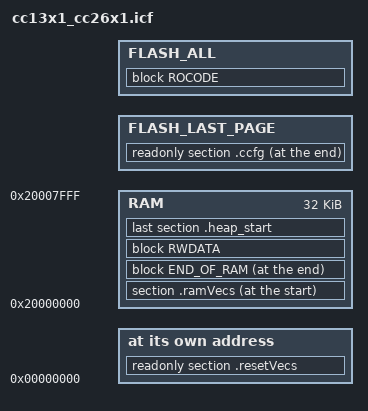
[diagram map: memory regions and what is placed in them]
/******************************************************************************

 @file  cc13x2_cc26x2.icf

 @brief IAR Linker configuration file for cc13x1_cc26x1

 Group: WCS LPC
 Target Device: cc13x2_cc26x2

 ******************************************************************************

 Copyright (c) 2016-2018, Texas Instruments Incorporated
 All rights reserved.

 Redistribution and use in source and binary forms, with or without
 modification, are permitted provided that the following conditions
 are met:

 *  Redistributions of source code must retain the above copyright
    notice, this list of conditions and the following disclaimer.

 *  Redistributions in binary form must reproduce the above copyright
    notice, this list of conditions and the following disclaimer in the
    documentation and/or other materials provided with the distribution.

 *  Neither the name of Texas Instruments Incorporated nor the names of
    its contributors may be used to endorse or promote products derived
    from this software without specific prior written permission.

 THIS SOFTWARE IS PROVIDED BY THE COPYRIGHT HOLDERS AND CONTRIBUTORS "AS IS"
 AND ANY EXPRESS OR IMPLIED WARRANTIES, INCLUDING, BUT NOT LIMITED TO,
 THE IMPLIED WARRANTIES OF MERCHANTABILITY AND FITNESS FOR A PARTICULAR
 PURPOSE ARE DISCLAIMED. IN NO EVENT SHALL THE COPYRIGHT OWNER OR
 CONTRIBUTORS BE LIABLE FOR ANY DIRECT, INDIRECT, INCIDENTAL, SPECIAL,
 EXEMPLARY, OR CONSEQUENTIAL DAMAGES (INCLUDING, BUT NOT LIMITED TO,
 PROCUREMENT OF SUBSTITUTE GOODS OR SERVICES; LOSS OF USE, DATA, OR PROFITS;
 OR BUSINESS INTERRUPTION) HOWEVER CAUSED AND ON ANY THEORY OF LIABILITY,
 WHETHER IN CONTRACT, STRICT LIABILITY, OR TORT (INCLUDING NEGLIGENCE OR
 OTHERWISE) ARISING IN ANY WAY OUT OF THE USE OF THIS SOFTWARE,
 EVEN IF ADVISED OF THE POSSIBILITY OF SUCH DAMAGE.

 *****************************************************************************/

////////////////////////////////////////////////////////////////////////////////
// Memory Sizes
////////////////////////////////////////////////////////////////////////////////
define symbol FLASH_BASE            = 0x00000000;
define symbol RAM_BASE              = 0x20000000;

define symbol RAM_SIZE            = 0x00008000; // 32K
define symbol FLASH_SIZE          = 0x00058000; // 352K

////////////////////////////////////////////////////////////////////////////////
// Memory Definitions
////////////////////////////////////////////////////////////////////////////////

////////////////////////////////////////////////////////////////////////////////
// RAM
//

define symbol RAM_START = RAM_BASE;
define symbol RAM_END = RAM_START+RAM_SIZE-1;

////////////////////////////////////////////////////////////////////////////////
// Flash
//
define symbol WORD_SIZE = 4;

define symbol PAGE_SIZE = 0x2000;
export symbol PAGE_SIZE;

define symbol FLASH_MEM_ALIGN     = WORD_SIZE;

define symbol FLASH_START           = FLASH_BASE;

define symbol NUM_RESERVED_PAGES    = 1;  /*last page i define in FLASH_LAST_PAGE */

define symbol RESERVED_SIZE         = (NUM_RESERVED_PAGES * PAGE_SIZE);

define symbol FLASH_END             = FLASH_SIZE - RESERVED_SIZE - 1;


////////////////////////////////////////////////////////////////////////////////
// Stack
//

define symbol STACK_SIZE          = 0x400;
define symbol STACK_START         = RAM_END + 1;
define symbol STACK_END           = STACK_START - STACK_SIZE;
//
define symbol STACK_TOP           = RAM_END + 1;
export symbol STACK_TOP;

////////////////////////////////////////////////////////////////////////////////
// Flash Interrupt Vector Table
//

define symbol INTVEC_NUM_ENTRIES  = 50 + 1; // first entry is stack location
define symbol INTVEC_SIZE         = INTVEC_NUM_ENTRIES + 4;

////////////////////////////////////////////////////////////////////////////////
// Memory Regions
////////////////////////////////////////////////////////////////////////////////

define memory mem with size = 4G;

define region RAM                 = mem:[from RAM_START   to RAM_END];
define region FLASH_LAST_PAGE     = mem:[from(FLASH_SIZE) - PAGE_SIZE to FLASH_SIZE-1];
define region FLASH               = mem:[from FLASH_START to FLASH_END];
define region FLASH_ALL           = mem:[from FLASH_START to FLASH_END] |
                                         FLASH_LAST_PAGE;

////////////////////////////////////////////////////////////////////////////////
// Memory Placement
////////////////////////////////////////////////////////////////////////////////

// Code and RO Data
define block ROCODE                           { ro };
//place in FLASH { readonly };

// CCFG
place at end of FLASH_LAST_PAGE { readonly section .ccfg };
keep { section .ccfg };

// Interrupt Vector Table
place at address mem:FLASH_START { readonly section .resetVecs };
keep                             { readonly section .resetVecs };

// All other pieces of codes:
place in FLASH_ALL { block ROCODE };

// RAM Vector Table
place at start of RAM { section .ramVecs };

// Runtime Stack
define block CSTACK with alignment = 8, size = STACK_SIZE { section .stack };

define block RWDATA { rw };

define section .heap_start            { public heapStart: };
define section .heap_end              { public heapEnd: };
define block   HEAP_END with size = 1 { section .heap_end };

define block END_OF_RAM with fixed order {
                                        block HEAP_END,
                                        block CSTACK
                                      };
place at end of RAM { block END_OF_RAM };

place in RAM { block RWDATA,
               last section .heap_start};
	       
////////////////////////////////////////////////////////////////////////////////
// Initialization
////////////////////////////////////////////////////////////////////////////////

initialize by copy { readwrite };

do not initialize
{
  section .noinit,
  section .stack,
};
